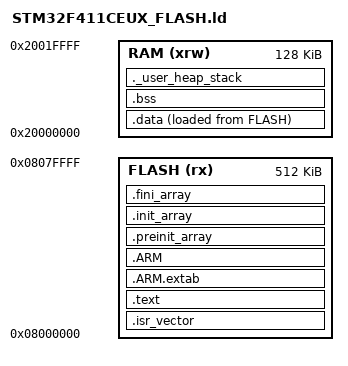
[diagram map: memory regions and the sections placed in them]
/* STM32F411xE/CE: 512 KB Flash, 128 KB SRAM */

ENTRY(Reset_Handler)

MEMORY
{
    FLASH (rx)  : ORIGIN = 0x08000000, LENGTH = 512K
    RAM   (xrw) : ORIGIN = 0x20000000, LENGTH = 128K
}

_estack = ORIGIN(RAM) + LENGTH(RAM);

/* Minimum heap/stack reserved in RAM for solvers that use malloc (cvxpygen/OSQP). */
_Min_Heap_Size  = 0x2000;   /* 8 KB */
_Min_Stack_Size = 0x1000;   /* 4 KB */

SECTIONS
{
    .isr_vector :
    {
        . = ALIGN(4);
        KEEP(*(.isr_vector))
        . = ALIGN(4);
    } >FLASH

    .text :
    {
        . = ALIGN(4);
        *(.text .text*)
        *(.rodata .rodata*)
        KEEP(*(.init))
        KEEP(*(.fini))
        . = ALIGN(4);
        _etext = .;
    } >FLASH

    .ARM.extab : { *(.ARM.extab* .gnu.linkonce.armextab.*) } >FLASH

    .ARM :
    {
        __exidx_start = .;
        *(.ARM.exidx* .gnu.linkonce.armexidx.*)
        __exidx_end = .;
    } >FLASH

    .preinit_array :
    {
        PROVIDE_HIDDEN (__preinit_array_start = .);
        KEEP(*(.preinit_array*))
        PROVIDE_HIDDEN (__preinit_array_end = .);
    } >FLASH

    .init_array :
    {
        PROVIDE_HIDDEN (__init_array_start = .);
        KEEP(*(SORT(.init_array.*)))
        KEEP(*(.init_array*))
        PROVIDE_HIDDEN (__init_array_end = .);
    } >FLASH

    .fini_array :
    {
        PROVIDE_HIDDEN (__fini_array_start = .);
        KEEP(*(SORT(.fini_array.*)))
        KEEP(*(.fini_array*))
        PROVIDE_HIDDEN (__fini_array_end = .);
    } >FLASH

    /* Initialised data: stored in Flash, copied to RAM at startup */
    .data :
    {
        . = ALIGN(4);
        _sdata = .;
        *(.data .data*)
        . = ALIGN(4);
        _edata = .;
    } >RAM AT>FLASH

    _sidata = LOADADDR(.data);

    .bss :
    {
        . = ALIGN(4);
        _sbss = .;
        *(.bss .bss*)
        *(COMMON)
        . = ALIGN(4);
        _ebss = .;
    } >RAM

    /* Heap and stack reservation */
    ._user_heap_stack :
    {
        . = ALIGN(8);
        PROVIDE(end  = .);
        PROVIDE(_end = .);
        . = . + _Min_Heap_Size;
        . = . + _Min_Stack_Size;
        . = ALIGN(8);
    } >RAM

    .ARM.attributes 0 : { *(.ARM.attributes) }
}
